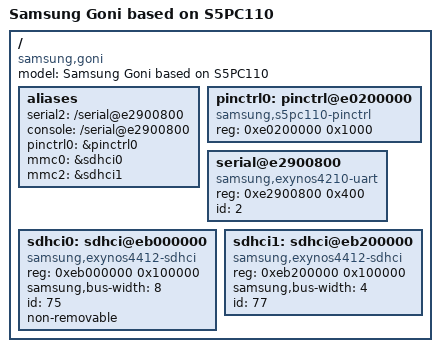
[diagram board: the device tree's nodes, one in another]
// SPDX-License-Identifier: GPL-2.0+
/*
 * Samsung's S5PC110-based Goni board device tree source
 *
 * Copyright (c) 2014 Google, Inc
 */

/dts-v1/;

#include "skeleton.dtsi"
#include "s5pc110-pinctrl.dtsi"

/ {
	model = "Samsung Goni based on S5PC110";
	compatible = "samsung,goni", "samsung,s5pc110";

	aliases {
		serial2 = "/serial@e2900800";
		console = "/serial@e2900800";
		pinctrl0 = &pinctrl0;
		mmc0 = &sdhci0;
		mmc2 = &sdhci1;
	};

	pinctrl0: pinctrl@e0200000 {
		compatible = "samsung,s5pc110-pinctrl";
		reg = <0xe0200000 0x1000>;
	};

	serial@e2900800 {
		compatible = "samsung,exynos4210-uart";
		reg = <0xe2900800 0x400>;
		id = <2>;
	};

	sdhci0:	sdhci@eb000000 {
        compatible = "samsung,exynos4412-sdhci";
        /*根据芯片手册得知*/
        reg = <0xeb000000 0x100000>;
        /*根据硬件原理图得知*/
        samsung,bus-width = <8>;
        /*设备id定义于arch/arm/mach-s5pc1xx/include/mach/periph.h*/
        id = <75>;
        /*通道0是eMMC不可热插拔*/
        non-removable;
        /*使能该设备*/
        status = "okay";
    };

	sdhci1:	sdhci@eb200000 {
        compatible = "samsung,exynos4412-sdhci";
        /*根据芯片手册得知*/
        reg = <0xeb200000 0x100000>;
        /*根据硬件原理图得知*/
        samsung,bus-width = <4>;
        /*设备id定义于arch/arm/mach-s5pc1xx/include/mach/periph.h*/
        id = <77>;
        /*通道0是eMMC不可热插拔*/
        //non-removable;
        /*使能该设备*/
        status = "okay";
    };

};
